# STM32WBA20xx register map
File version: 1.0
Registers are 32-bit, read-write, reset 0x0 unless marked. A register's access mark holds for its fields unless they carry their own. Offsets are from the block's base; [hi:lo] are bit positions; {n}, {i} and the like mark numbered series; 'fields as' and 'values as' point back to an identical list.

## RAMCFG
Base 0x40026000
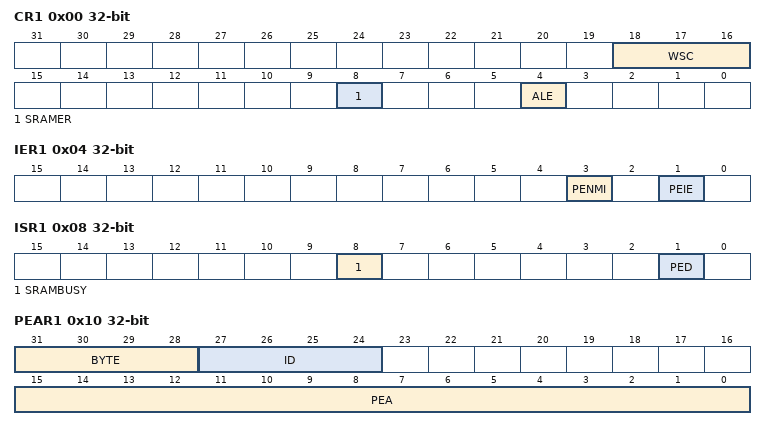
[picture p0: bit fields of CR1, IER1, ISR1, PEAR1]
0x00 CR1 — Control Register
  [18:16] WSC — WSC[18:16] Wait State Configuration field
  [8] SRAMER — Start Erase
  [4] ALE — Address Latching Enable
0x04 IER1 — Interrupt enable register
  [3] PENMI — Parity error NMI
  [1] PEIE — Parity error interrupt enable
0x08 ISR1 — Interrupt status register
  [8] SRAMBUSY — SRAM busy with erase operation
  [1] PED — Parity error detected
0x10 PEAR1 — Parity error address register
  [31:28] BYTE — Byte parity error flag
  [27:24] ID — Parity error AHB bus master ID
  [15:0] PEA — Parity error SRAM word aligned address offset
0x14 ICR1 — Interrupt clear register
  [1] CPED — Clear parity error detect bit
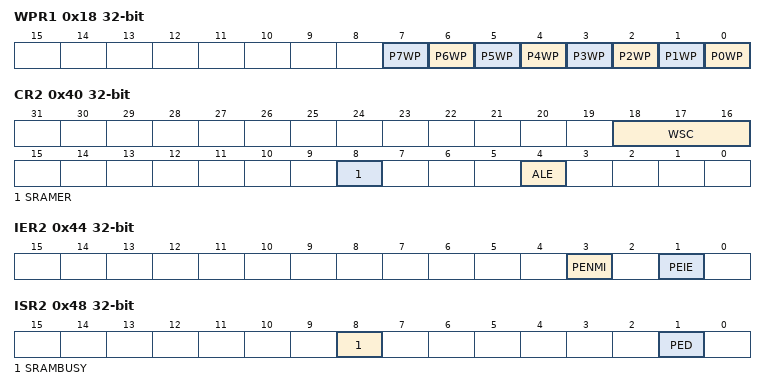
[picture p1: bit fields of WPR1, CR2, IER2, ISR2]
0x18 WPR1 — Write protection register 1
  [n] P{n}WP (n=0..7) — Write Protection Page {n:02}
0x28 ERKEYR1 — Erase key register
  [7:0] ERASEKEY — Erase write protection key
0x40 CR2 — Control Register
  fields as CR1
0x44 IER2 — Interrupt enable register
  fields as IER1
0x48 ISR2 — Interrupt status register
  fields as ISR1
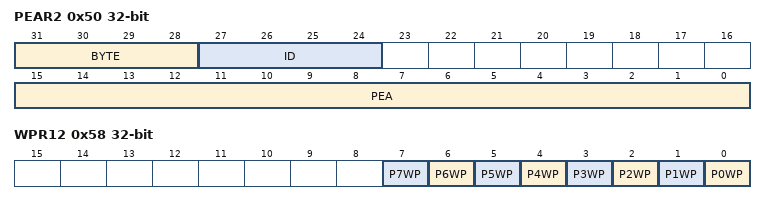
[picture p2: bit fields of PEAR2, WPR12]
0x50 PEAR2 — Parity error address register
  fields as PEAR1
0x54 ICR2 — Interrupt clear register
  [1] CPED — Clear parity error detect bit
0x58 WPR12 — Write protection register 1
  [n] P{n}WP (n=0..7) — Write Protection Page {n:02}
0x68 ERKEYR2 — Erase key register
  [7:0] ERASEKEY — Erase write protection key

## ICACHE — Instruction Cache
Base 0x40030400
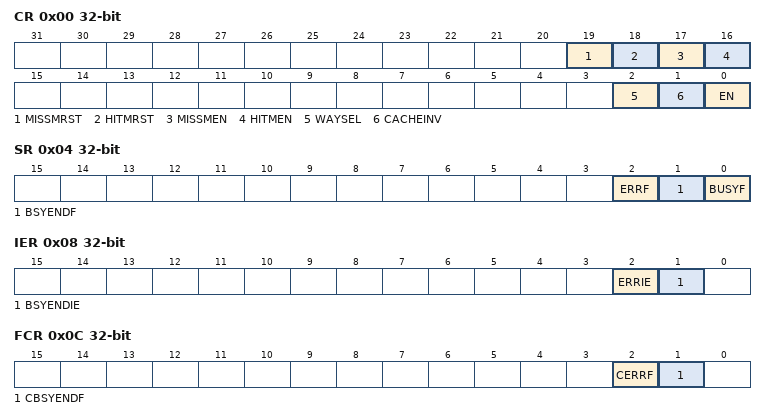
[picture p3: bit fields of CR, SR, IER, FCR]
0x00 CR — ICACHE control register
  [19] MISSMRST — Miss monitor reset
  [18] HITMRST — Hit monitor reset
  [17] MISSMEN — Miss monitor enable
  [16] HITMEN — Hit monitor enable
  [2] WAYSEL — Ways selection
    0=ICACHE_1WAY (1-way cache (direct mapped cache)); 1=ICACHE_2WAYS (2-ways set associative cache (default))
  [1] CACHEINV — Cache invalidation
  [0] EN — Enable
0x04 SR — ICACHE status register
  [2] ERRF — Cache error flag
  [1] BSYENDF — Busy end flag
  [0] BUSYF — Busy flag
0x08 IER — ICACHE interrupt enable register
  [2] ERRIE — Cache error interrupt enable
  [1] BSYENDIE — Busy end interrupt enable
0x0C FCR — ICACHE Flag clear register
  [2] CERRF — Cache error flag clear
  [1] CBSYENDF — Busy end flag clear
0x10 HMONR — ICACHE hit monitor register
  [31:0] HITMON — Cache hit monitor register
0x14 MMONR — ICACHE miss monitor register
  [15:0] MISSMON — Cache miss monitor register
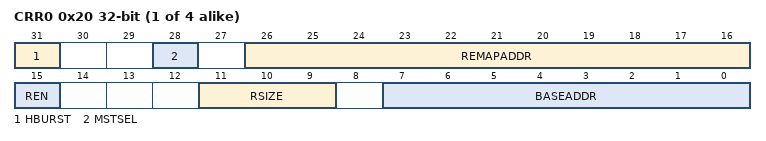
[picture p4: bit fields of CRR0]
{0x20+4i} CRR{i} (i=0..3) — ICACHE region {i} configuration register
  [31] HBURST — Region X output burst type
  [28] MSTSEL — Region X AHB cache master selection
  [26:16] REMAPADDR — Remap address of Region X to be remapped
  [15] REN — Region X enable
  [11:9] RSIZE — Region X size
  [7:0] BASEADDR — Base address of region X to remap

## GPIOA — General Purpose I/O
Base 0x42020000
Same registers: GPIOB 0x42020400, GPIOC 0x42020800, GPIOH 0x42021C00
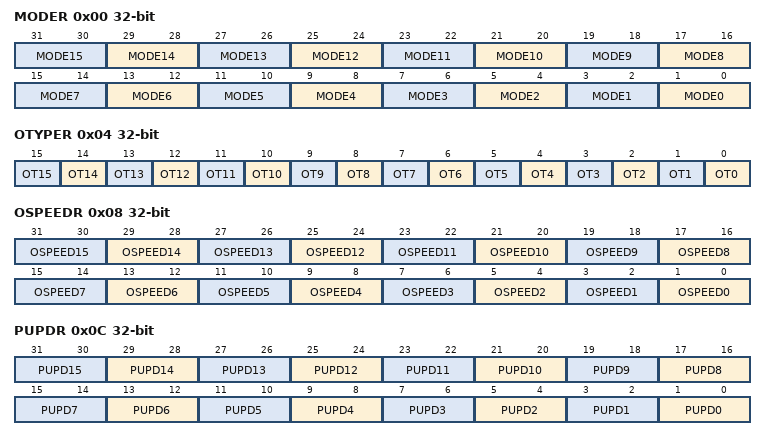
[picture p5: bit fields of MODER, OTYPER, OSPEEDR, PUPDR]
0x00 MODER — GPIO port mode register
  [2n+1:2n] MODE{n} (n=0..15)
0x04 OTYPER — GPIO port output type register
  [n] OT{n} (n=0..15)
0x08 OSPEEDR — GPIO port output speed register
  [2n+1:2n] OSPEED{n} (n=0..15)
0x0C PUPDR — GPIO port pull-up/pull-down register
  [2n+1:2n] PUPD{n} (n=0..15)
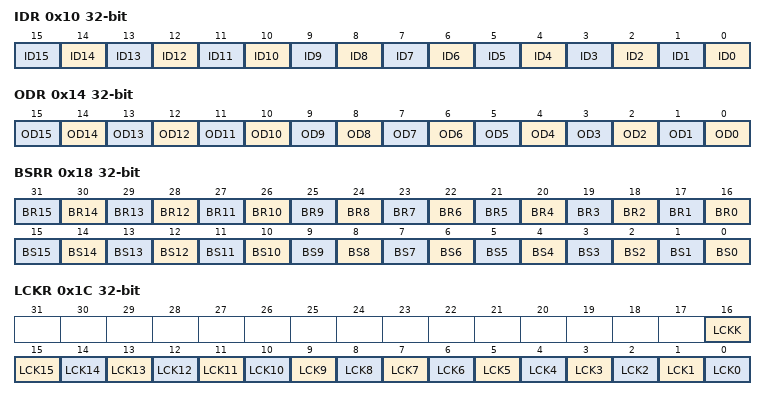
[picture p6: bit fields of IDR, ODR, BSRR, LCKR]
0x10 IDR — GPIO port input data register
  [n] ID{n} (n=0..15)
0x14 ODR — GPIO port output data register
  [n] OD{n} (n=0..15)
0x18 BSRR — GPIO port bit set/reset register
  [n+16] BR{n} (n=0..15), [n] BS{n} (n=0..15)
0x1C LCKR — GPIO port configuration lock register
  [16] LCKK, [n] LCK{n} (n=0..15)
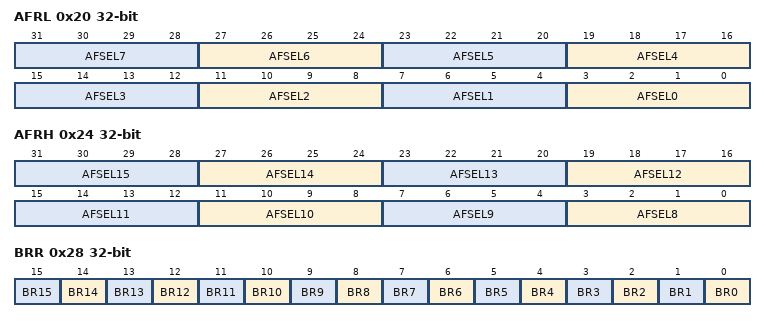
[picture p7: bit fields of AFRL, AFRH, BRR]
0x20 AFRL — GPIO alternate function registers
  [4n+3:4n] AFSEL{n} (n=0..7)
0x24 AFRH — GPIO alternate function registers
  [4n-29:4n-32] AFSEL{n} (n=8..15)
0x28 BRR — GPIO Bit Reset register
  [n] BR{n} (n=0..15)

## AES — AES hardware accelerator
Base 0x420C0000
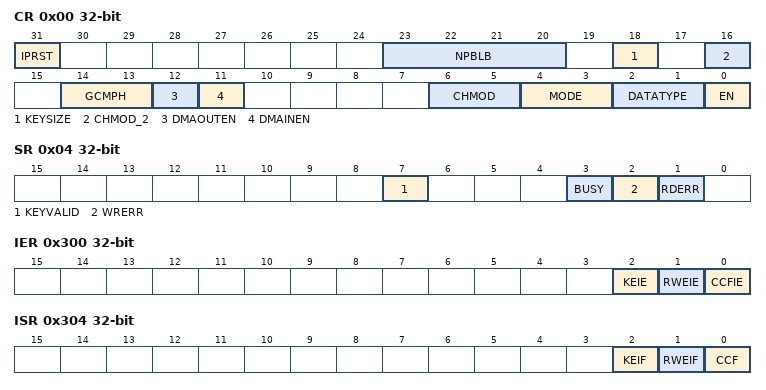
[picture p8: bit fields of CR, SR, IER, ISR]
0x00 CR — AES control register
  [31] IPRST — AES IP software reset
  [23:20] NPBLB — Number of padding bytes in payload last block
  [18] KEYSIZE — Key size selection
  [16] CHMOD_2 — AES Chaining Mode
  [14:13] GCMPH — GCM Phase
  [12] DMAOUTEN — Enable data output phase DMA management
  [11] DMAINEN — Enable data input phase DMA management
  [6:5] CHMOD — AES Chaining Mode
  [4:3] MODE — AES Mode Of Operation
  [2:1] DATATYPE — Data type selection
  [0] EN — AES Enable
0x04 SR — AES status register
  [7] KEYVALID — Key Valid Flag
  [3] BUSY — Busy Flag
  [2] WRERR — Write Error Flag
  [1] RDERR — Read Error Flag
0x08 DINR — AES data input register
  [31:0] DINR — AES Data Input Register
0x0C DOUTR — AES data output register
  [31:0] DOUTR — AES Data Output Register
{0x10+4i} KEYR{i} (i=0..3) — AES key register {i}
  [31:0] KEYR{i} — AES Key Register {i}
{0x20+4i} IVR{i} (i=0..3) — AES initialization vector register {i}
  [31:0] IVR{i} — AES Initialization Vector Register {i}
{0x20+4i} KEYR{i} (i=4..7) — AES key register {i}
  [31:0] KEYR{i} — AES Key Register {i}
{0x40+4i} SUSP{i}R (i=0..7) — AES Suspend register {i}
  [31:0] SUSP{i}R — AES Suspend registers {i}
0x300 IER — AES Interrupt Enable Register
  [2] KEIE — Key error interrupt enable
  [1] RWEIE — Read or write error Interrupt Enable
  [0] CCFIE — Computation complete flag interrupt enable
0x304 ISR — AES Interrupt Status Register
  [2] KEIF — Key error interrupt flag
  [1] RWEIF — Read or write error Interrupt flag
  [0] CCF — Computation complete flag
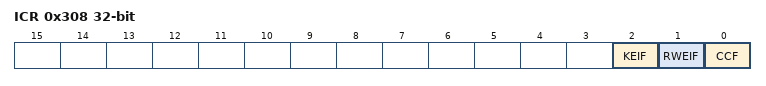
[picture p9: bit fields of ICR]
0x308 ICR — AES Interrupt Clear Register
  [2] KEIF — Key error interrupt flag clear
  [1] RWEIF — Read or write error Interrupt flag clear
  [0] CCF — Computation complete flag clear
